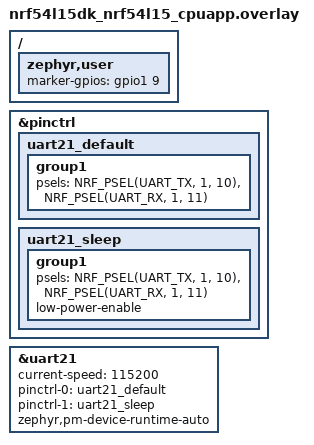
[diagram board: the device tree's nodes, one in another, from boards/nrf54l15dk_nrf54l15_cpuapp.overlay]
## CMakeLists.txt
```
cmake_minimum_required(VERSION 3.20.0)

find_package(Zephyr REQUIRED HINTS $ENV{ZEPHYR_BASE})
project(lab3_device_pm)

target_sources(app PRIVATE src/main.c)
```

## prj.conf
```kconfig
# Lab 3 - Device Power Management (Runtime PM)
#
# This build demonstrates Device Runtime PM on a secondary UART instance
# (see boards/nrf54l15dk_nrf54l15_cpuapp.overlay). There is no CONFIG_PM
# here - it cannot be selected on this SoC (see workshop Module 1.4/2.1).
#
# Zephyr also offers System-Managed Device PM (CONFIG_PM_DEVICE_SYSTEM_MANAGED)
# as an alternative to Runtime PM on SoCs that have real system PM. It is
# intentionally NOT used here: its trigger is the CPU-level sleep transition
# that CONFIG_PM's idle thread would drive, and that transition does not
# exist on this SoC - so system-managed device PM would have nothing to
# hook into. Device Runtime PM has no such dependency, which is exactly
# why it is the only device-PM model this workshop uses on this board.

CONFIG_PM_DEVICE=y
CONFIG_PM_DEVICE_RUNTIME=y

# --- GPIO for the LED and the PPK2 marker pin ---
CONFIG_GPIO=y

# --- The peripheral we runtime-PM: a secondary UART instance ---
CONFIG_SERIAL=y

# --- Disable Logging  ---
CONFIG_CONSOLE=n
CONFIG_UART_CONSOLE=n
CONFIG_LOG=n
```

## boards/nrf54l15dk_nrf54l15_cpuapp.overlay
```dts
/*
 * Lab 3 board overlay
 *
 * Adds:
 *   1. A "zephyr,user" marker-gpios entry: a spare pin you can wire a PPK2
 *      digital input to, toggled around pm_device_runtime_get()/put() calls
 *      so the PM transition is directly visible on the current trace
 *      (workshop Module 3, Step 3.6).
 *
 *      Default: gpio1 pin 9 (a header pin not used by the DK's LEDs/buttons
 *      on most revisions). Change the controller/pin below if it conflicts
 *      with your setup.
 *
 *   2. Enables a secondary UART instance and marks it for automatic Device
 *      Runtime PM via the "zephyr,pm-device-runtime-auto" property, per
 *      workshop Lab 3, Step 3.2.
 *
 *      Adjust "uart21" below to whichever secondary UARTE instance is free
 *      on your exact nRF54L15 DK revision / NCS version - check your SoC's
 *      .dtsi for the available uartNN node labels if the build fails to
 *      find this node.
 *
 *   3. Pinctrl states for that UART instance. The nordic,nrf-uarte binding
 *      REQUIRES pinctrl-0 (build fails with a devicetree error otherwise -
 *      "'pinctrl-0' is marked as required... but does not appear in").
 *      TX/RX below are mapped to P1.10 / P1.11, which are not used by any
 *      LED, button, or on-board peripheral on the nRF54L15 DK - but always
 *      double-check against your board revision's schematic/user guide
 *      before wiring anything to these pins physically. If you only need
 *      Device Runtime PM's suspend/resume behaviour (no actual bytes on the
 *      wire), any free GPIO pair works; nothing needs to be physically
 *      connected to them for this lab.
 */

#include <zephyr/dt-bindings/gpio/gpio.h>
#include <zephyr/dt-bindings/pinctrl/nrf-pinctrl.h>

/ {
	zephyr,user {
		marker-gpios = <&gpio1 9 GPIO_ACTIVE_HIGH>;
	};
};

&pinctrl {
	uart21_default: uart21_default {
		group1 {
			psels = <NRF_PSEL(UART_TX, 1, 10)>,
				<NRF_PSEL(UART_RX, 1, 11)>;
		};
	};

	uart21_sleep: uart21_sleep {
		group1 {
			psels = <NRF_PSEL(UART_TX, 1, 10)>,
				<NRF_PSEL(UART_RX, 1, 11)>;
			low-power-enable;
		};
	};
};

&uart21 {
	status = "okay";
	current-speed = <115200>;
	pinctrl-0 = <&uart21_default>;
	pinctrl-1 = <&uart21_sleep>;
	pinctrl-names = "default", "sleep";
	zephyr,pm-device-runtime-auto;
};
```

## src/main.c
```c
/*
 * Lab 3 - Device Power Management
 *
 * Demonstrates Device Runtime PM: pm_device_runtime_get()/put() bracketing
 * an intermittent UART transaction on a peripheral marked
 * "zephyr,pm-device-runtime-auto" in the board overlay, with a
 * PPK2-visible marker GPIO toggled around each transaction.
 */

#include <zephyr/kernel.h>
#include <zephyr/device.h>
#include <zephyr/devicetree.h>
#include <zephyr/drivers/gpio.h>
#include <zephyr/drivers/uart.h>
#include <zephyr/pm/device_runtime.h>
#include <zephyr/sys/printk.h>

#define LED0_NODE    DT_ALIAS(led0)
#define MARKER_NODE  DT_PATH(zephyr_user)
#define DEMO_UART    DT_NODELABEL(uart21)

static const struct gpio_dt_spec led    = GPIO_DT_SPEC_GET(LED0_NODE, gpios);
static const struct gpio_dt_spec marker = GPIO_DT_SPEC_GET(MARKER_NODE, marker_gpios);
static const struct device *demo_uart   = DEVICE_DT_GET(DEMO_UART);

#define IDLE_PERIOD_MS    1500
#define BURST_LEN_BYTES   8
#define VISIBILITY_HOLD_MS 60

static void send_demo_burst(void)
{
	static uint8_t seq;
	int ret;

	/* Mark the start of the transaction on the PPK2 trace. */
	gpio_pin_set_dt(&marker, 1);

	/*
	 * Device Runtime PM: ask for the device. If it was suspended, it is
	 * resumed here (synchronously) before the call returns.
	 */
	ret = pm_device_runtime_get(demo_uart);
	if (ret < 0) {
		printk("pm_device_runtime_get failed: %d\n", ret);
		gpio_pin_set_dt(&marker, 0);
		return;
	}

	for (int i = 0; i < BURST_LEN_BYTES; i++) {
		uart_poll_out(demo_uart, (uint8_t)(seq + i));
	}
	seq++;

	/*
	 * The actual burst above is well under 1 ms (8 bytes at 115200
	 * baud) - too short to see on a PPK2 trace at a normal, multi-second
	 * zoom level. Hold the marker high (and the device held active via
	 * runtime PM) for a bit longer purely so the pulse is easy to spot
	 * without having to zoom in to a few milliseconds at exactly the
	 * right moment. Remove this hold once you're comfortable finding
	 * the real, much shorter pulse in a zoomed-in view.
	 */
	k_msleep(VISIBILITY_HOLD_MS);

	/*
	 * Release our usage reference. If nobody else holds one, the device
	 * is suspended right away.
	 */
	ret = pm_device_runtime_put(demo_uart);
	if (ret < 0) {
		printk("pm_device_runtime_put failed: %d\n", ret);
	}

	/* Mark the end of the transaction on the PPK2 trace. */
	gpio_pin_set_dt(&marker, 0);

	printk("Sent %d-byte burst over %s (runtime PM get/put around it, "
	       "marker held %d ms for visibility)\n",
	       BURST_LEN_BYTES, demo_uart->name, VISIBILITY_HOLD_MS);
}

int main(void)
{
	printk("Lab 3: PM_DEVICE_RUNTIME=%d\n",
	       IS_ENABLED(CONFIG_PM_DEVICE_RUNTIME));

	if (!gpio_is_ready_dt(&led) || !gpio_is_ready_dt(&marker)) {
		printk("Error: GPIO device(s) not ready\n");
		return 0;
	}

	gpio_pin_configure_dt(&led, GPIO_OUTPUT_ACTIVE);
	gpio_pin_configure_dt(&marker, GPIO_OUTPUT_INACTIVE);

	if (!device_is_ready(demo_uart)) {
		printk("Error: demo UART device not ready\n");
		return 0;
	}

	/*
	 * With "zephyr,pm-device-runtime-auto" set in the overlay, the
	 * device already starts suspended - no explicit
	 * pm_device_runtime_enable() call is needed here.
	 */

	while (1) {
		gpio_pin_toggle_dt(&led);

		send_demo_burst();

		/*
		 * Idle window between bursts: with Device Runtime PM, the
		 * UART instance is suspended for this entire window even
		 * though the LED toggle loop itself keeps running.
		 */
		k_msleep(IDLE_PERIOD_MS);
	}

	return 0;
}
```
